# ESP32-P4 register map
Vendor: ESPRESSIF SYSTEMS (SHANGHAI) CO., LTD.; Series: ESP32 P-Series; File version: 3
CPU: RV32IMAFC r0p0, little endian, no MPU, FPU, 0 interrupt priority bits
Address unit: 32 bits
Registers are 32-bit, read-write, reset 0x0 unless marked. A register's access mark holds for its fields unless they carry their own. Offsets are from the block's base; [hi:lo] are bit positions; {n}, {i} and the like mark numbered series.

## CLINT — Core Local Interrupts
Base 0x20000000
Same registers: CLINT_OTHER_CORE 0x20010000
0x00 MSIP — Core-local machine software interrupt pending register
  [0] MSIP — Configures the pending status of the machine software interrupt.
0x4000 MTIMECMP 64-bit (reset mask 0xFFFFFFFF) — Core-local machine timer compare value
  [63:0] MTIMECMP — Represents the value to compare with the system counter.
0x4008 MTIMELOAD 64-bit (reset mask 0xFFFFFFFF) — Core-local machine timer load value
  [63:0] MTIMELOAD — Represents the value to be loaded to the system counter.
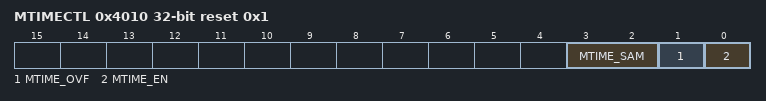
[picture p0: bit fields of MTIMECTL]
0x4010 MTIMECTL reset 0x1 — Core-local machine timer interrupt control/status register
  [3:2] MTIME_SAM — Configures the sampling mode of MTIME, to allow reading the 64-bit counter value consistently.
    0=NONE (No sampling); 1=SAMPLE_HIGH (Sample the upper half of the system counter when the lower half of MTIME is read); 2=SAMPLE_LOW (Sample the lower half of the system counter when the upper half of MTIME is read); 3=SAMPLE_OTHER (Sample the other half of the system counter when either half of MTIME is read)
  [1] MTIME_OVF — Set by hardware when the system counter reaches its maximum value. Software can clear this bit by writing 0 to it.
  [0] MTIME_EN — Configures whether to enable the system counter. This bit is implemented in the CLINT of core 0 only.
0xBFF8 MTIME 64-bit ro (reset mask 0xFFFFFFFF) — Core-local system counter value
  [63:0] MTIME — Represents the current value of the system counter.

## CLIC — Core Local Interrupt Controller
Base 0x20800000
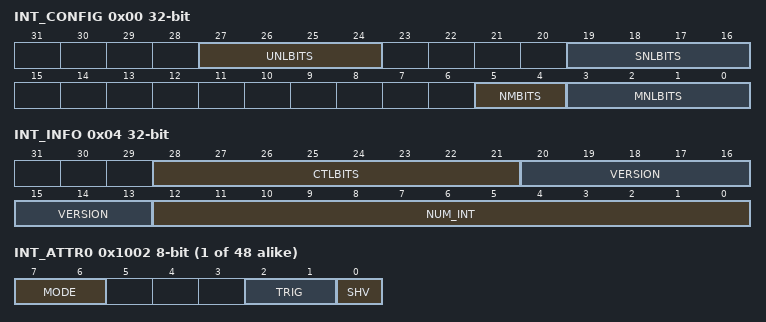
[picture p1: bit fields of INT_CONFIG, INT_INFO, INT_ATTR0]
0x00 INT_CONFIG
  [27:24] UNLBITS — User mode interrupt priority effective digits, the maximum value is 8.
  [19:16] SNLBITS — Supervisor mode interrupt priority effective digits, the maximum value is 8.
  [5:4] NMBITS — The effective number of bits in the privileged state.
  [3:0] MNLBITS — Machine mode interrupt priority effective digits, the maximum value is 8.
0x04 INT_INFO ro
  [28:21] CTLBITS — The effective bits of priority in the CLICINTCTL register.
  [20:13] VERSION — The lower 4 bits are the modified version of the hardware implementation; the upper 4 bits are the CLIC architecture version information.
  [12:0] NUM_INT — The number of interrupt sources.
{0x1000+4i} INT_IP{i} (i=0..47) 8-bit — Interrupt pending register.
  [0] INT_IP — Interrupt pending bit.
{0x1001+4i} INT_IE{i} (i=0..47) 8-bit — Interrupt enable register.
  [0] INT_IE — Interrupt enable bit.
{0x1002+4i} INT_ATTR{i} (i=0..47) 8-bit access per field — Interrupt attribute register.
  [7:6] MODE ro — Configures the privilege mode of the ith CLIC interrupt. This is hardwired to 0x3 as user mode interrupts are not supported.
  [2:1] TRIG rw — Configures the trigger type and polarity of the ith CLIC machine mode interrupt.
    0=POSITIVE_LEVEL (interrupt is positive level-triggered); 1=POSITIVE_EDGE (interrupt is positive edge-triggered); 2=NEGATIVE_LEVEL (interrupt is negative level-triggered); 3=NEGATIVE_EDGE (interrupt is negative edge-triggered)
  [0] SHV rw — Configures hardware vectoring for the ith CLIC machine mode interrupt.
    0=SOFTWARE (Not hardware vectored. Upon taking this interrupt, the CPU will jump to the address configured in mtvec.); 1=HARDWARE (Hardware vectored. Upon taking this interrupt, the CPU will jump to the word address stored at (mtvt + 4*i) relative to the base address configured in mtvt.)
{0x1003+4i} INT_CTL{i} (i=0..47) 8-bit access per field — Interrupt level control register.
  [7:5] CTL rw — Configures the level and priority of the ith CLIC machine mode interrupt.
